VERSION ""

NS_ :

BS_:

BU_: ECM ABS BCM

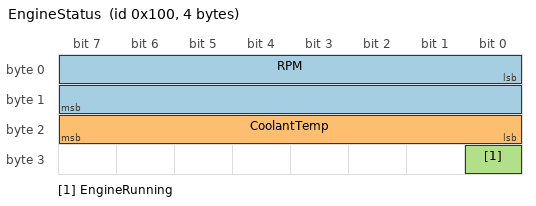
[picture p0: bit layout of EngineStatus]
BO_ 256 EngineStatus: 4 ECM
 SG_ RPM : 0|16@1+ (1,0) [0|8000] "rpm" BCM
 SG_ CoolantTemp : 16|8@1+ (1,-40) [-40|215] "degC" BCM
 SG_ EngineRunning : 24|1@1+ (1,0) [0|1] "" BCM

BO_ 257 VehicleSpeed: 2 ABS
 SG_ Speed : 0|16@1+ (0.1,0) [0|500] "km/h" BCM

BO_ 258 BrakeStatus: 3 ABS
 SG_ BrakePedal : 0|8@1+ (1,0) [0|1] "" BCM
 SG_ BrakePressure : 8|16@1+ (1,0) [0|500] "bar" BCM

CM_ BO_ 256 "Estado de motor: RPM, temperatura de refrigerante y estado de marcha. Simulado en StartCanTxTask.";
CM_ BO_ 257 "Velocidad de vehiculo (ABS/ESP). Simulada en StartVehicleTxTask.";
CM_ BO_ 258 "Estado de freno: pedal presionado + presion de linea. Simulada en StartVehicleTxTask.";
